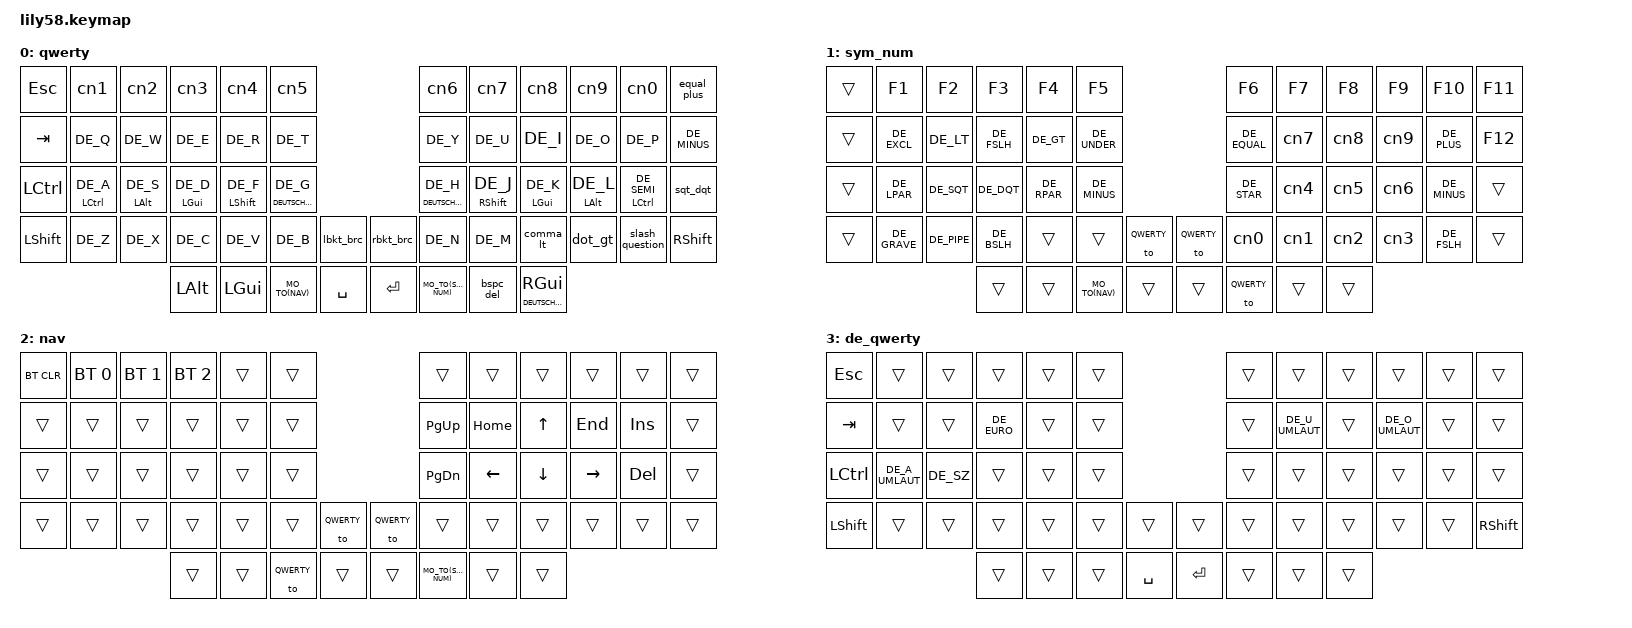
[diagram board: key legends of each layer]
#define HOST_OS 2

#include <behaviors.dtsi>
#include <dt-bindings/zmk/keys.h>
#include <dt-bindings/zmk/bt.h>
#include <dt-bindings/zmk/ext_power.h>
#include <dt-bindings/zmk/outputs.h>
#include <locale/keys_de.h>

#include "zmk-helpers/helper.h"
#include "zmk-helpers/key-labels/lily58.h"
#include "zmk-helpers/unicode-chars/german.dtsi"

#include "custom_numbers.h"

#define ___ &trans

// left hand keys
#define KEYS_L LT5 LT4 LT3 LT2 LT1 LT0 LM5 LM4 LM3 LM2 LM1 LM0 LB5 LB4 LB3 LB2 LB1 LB0 LF5 LF4 LF3 LF2 LF1 LF0 LEC
// right hand keys
#define KEYS_R RT5 RT4 RT3 RT2 RT1 RT0 RM5 RM4 RM3 RM2 RM1 RM0 RB5 RB4 RB3 RB2 RB1 RB0 RF5 RF4 RF3 RF2 RF1 RF0 REC
// thumb keys
#define THUMBS LH3 LH2 LH1 LH0 RH0 RH1 RH2 RH3

// layer definitions
#define QWERTY          0
#define SYM_NUM         1
#define NAV             2
#define DEUTSCH_QWERTY  3

ZMK_HOLD_TAP(mo_to,
    flavor = "balanced";
    tapping-term-ms = <200>;
    bindings = <&mo>, <&to>;
)

#define MO_TO(layer) &mo_to layer layer

// left-hand HRMs
ZMK_HOLD_TAP(hml,
    flavor = "balanced";
    tapping-term-ms = <280>;
    quick-tap-ms = <175>;                // repeat on tap-into-hold
    require-prior-idle-ms = <150>;
    bindings = <&kp>, <&kp>;
    hold-trigger-key-positions = <KEYS_R THUMBS>;
    hold-trigger-on-release;             // delay positional check until key-release
)

// right-hand HRMs
ZMK_HOLD_TAP(hmr,
    flavor = "balanced";
    tapping-term-ms = <280>;
    quick-tap-ms = <175>;                // repeat on tap-into-hold
    require-prior-idle-ms = <150>;
    bindings = <&kp>, <&kp>;
    hold-trigger-key-positions = <KEYS_L THUMBS>;
    hold-trigger-on-release;             // delay p ositional check until key-release
)

// tap: backspace | shift + tap: delete
ZMK_MOD_MORPH(bspc_del,
     bindings = <&kp BSPC>, <&kp DEL>;
     mods = <(MOD_LSFT|MOD_RSFT)>;
)

#define HRM_CTRL_A &hml LCTRL DE_A
#define HRM_ALT_S &hml LALT DE_S
#define HRM_GUI_D &hml LGUI DE_D
#define HRM_SHIFT_F &hml LSHIFT DE_F
#define HRM_DQ_G &lt DEUTSCH_QWERTY DE_G
#define HRM_DQ_H &lt DEUTSCH_QWERTY DE_H
#define HRM_SHIFT_J &hmr RSHIFT DE_J
#define HRM_GUI_K &hmr LGUI DE_K
#define HRM_ALT_L &hmr LALT DE_L
#define HRM_CTRL_SEMI &hmr LCTRL DE_SEMI
ZMK_LAYER(qwerty,
    // ╭────────────────┬────────────────┬────────────────┬────────────────┬────────────────┬────────────────┬────────────────╮╭────────────────┬────────────────┬────────────────┬────────────────┬────────────────┬────────────────┬────────────────╮
         &kp ESC          &cn1             &cn2             &cn3             &cn4             &cn5                                                &cn6             &cn7             &cn8             &cn9             &cn0             &equal_plus
    // ├────────────────┼────────────────┼────────────────┼────────────────┼────────────────┤────────────────┤────────────────┤├────────────────┼────────────────┼────────────────┼────────────────┼────────────────┤────────────────┤────────────────┤
         &kp TAB          &kp DE_Q         &kp DE_W         &kp DE_E         &kp DE_R         &kp DE_T                                            &kp DE_Y         &kp DE_U         &kp DE_I         &kp DE_O         &kp DE_P         &kp DE_MINUS
    // ├────────────────┼────────────────┼────────────────┼────────────────┼────────────────┤────────────────┤────────────────┤├────────────────┼────────────────┼────────────────┼────────────────┼────────────────┤────────────────┤────────────────┤
         &kp LCTRL        HRM_CTRL_A       HRM_ALT_S        HRM_GUI_D        HRM_SHIFT_F      HRM_DQ_G                                            HRM_DQ_H         HRM_SHIFT_J      HRM_GUI_K        HRM_ALT_L        HRM_CTRL_SEMI    &sqt_dqt
    // ├────────────────┼────────────────┼────────────────┼────────────────┼────────────────┤────────────────┤────────────────┤├────────────────┼────────────────┼────────────────┼────────────────┼────────────────┤────────────────┤────────────────┤
         &kp LSHFT        &kp DE_Z         &kp DE_X         &kp DE_C         &kp DE_V         &kp DE_B         &lbkt_brc         &rbkt_brc        &kp DE_N         &kp DE_M         &comma_lt        &dot_gt          &slash_question  &kp RSHIFT
    // ├────────────────┼────────────────┼────────────────┼────────────────┼────────────────┤────────────────┤────────────────┤├────────────────┼────────────────┼────────────────┼────────────────┼────────────────┤────────────────┤────────────────┤
                                                            &kp LALT         &kp LGUI         MO_TO(NAV)       &kp SPACE         &kp ENTER        MO_TO(SYM_NUM)   &bspc_del        &lt DEUTSCH_QWERTY RGUI
    //                                                    ╰────────────────┴────────────────┴────────────────┴────────────────╯╰────────────────┴────────────────┴────────────────┴────────────────╯
)

ZMK_LAYER(sym_num,
    // ╭────────────────┬────────────────┬────────────────┬────────────────┬────────────────┬────────────────┬────────────────╮╭────────────────┬────────────────┬────────────────┬────────────────┬────────────────┬────────────────┬────────────────╮
         ___              &kp F1           &kp F2           &kp F3           &kp F4           &kp F5                                              &kp F6           &kp F7           &kp F8           &kp F9           &kp F10          &kp F11      
    // ├────────────────┼────────────────┼────────────────┼────────────────┼────────────────┤────────────────┤────────────────┤├────────────────┼────────────────┼────────────────┼────────────────┼────────────────┤────────────────┤────────────────┤
         ___              &kp DE_EXCL      &kp DE_LT        &kp DE_FSLH      &kp DE_GT        &kp DE_UNDER                                        &kp DE_EQUAL     &cn7             &cn8             &cn9             &kp DE_PLUS      &kp F12
    // ├────────────────┼────────────────┼────────────────┼────────────────┼────────────────┤────────────────┤────────────────┤├────────────────┼────────────────┼────────────────┼────────────────┼────────────────┤────────────────┤────────────────┤
         ___              &kp DE_LPAR      &kp DE_SQT       &kp DE_DQT       &kp DE_RPAR      &kp DE_MINUS                                        &kp DE_STAR      &cn4             &cn5             &cn6             &kp DE_MINUS     ___
    // ├────────────────┼────────────────┼────────────────┼────────────────┼────────────────┤────────────────┤────────────────┤├────────────────┼────────────────┼────────────────┼────────────────┼────────────────┤────────────────┤────────────────┤
         ___              &kp DE_GRAVE     &kp DE_PIPE      &kp DE_BSLH      ___              ___              &to QWERTY        &to QWERTY       &cn0             &cn1             &cn2             &cn3             &kp DE_FSLH      ___
    // ├────────────────┼────────────────┼────────────────┼────────────────┼────────────────┤────────────────┤────────────────┤├────────────────┼────────────────┼────────────────┼────────────────┼────────────────┤────────────────┤────────────────┤
                                                            ___              ___              MO_TO(NAV)       ___               ___              &to QWERTY       ___              ___
    //                                                    ╰────────────────┴────────────────┴────────────────┴────────────────╯╰────────────────┴────────────────┴────────────────┴────────────────╯
)

ZMK_LAYER(nav,
    // ╭────────────────┬────────────────┬────────────────┬────────────────┬────────────────┬────────────────┬────────────────╮╭────────────────┬────────────────┬────────────────┬────────────────┬────────────────┬────────────────┬────────────────╮
         &bt BT_CLR       &bt BT_SEL 0     &bt BT_SEL 1     &bt BT_SEL 2     ___              ___                                                 ___              ___              ___              ___              ___              ___
    // ├────────────────┼────────────────┼────────────────┼────────────────┼────────────────┤────────────────┤────────────────┤├────────────────┼────────────────┼────────────────┼────────────────┼────────────────┤────────────────┤────────────────┤
         ___              ___              ___              ___              ___              ___                                                 &kp PG_UP        &kp HOME         &kp UP           &kp END          &kp INS          ___
    // ├────────────────┼────────────────┼────────────────┼────────────────┼────────────────┤────────────────┤────────────────┤├────────────────┼────────────────┼────────────────┼────────────────┼────────────────┤────────────────┤────────────────┤
         ___              ___              ___              ___              ___              ___                                                 &kp PG_DN        &kp LEFT         &kp DOWN         &kp RIGHT        &kp DEL          ___
    // ├────────────────┼────────────────┼────────────────┼────────────────┼────────────────┤────────────────┤────────────────┤├────────────────┼────────────────┼────────────────┼────────────────┼────────────────┤────────────────┤────────────────┤
         ___              ___              ___              ___              ___              ___              &to QWERTY        &to QWERTY       ___              ___              ___              ___              ___              ___
    // ├────────────────┼────────────────┼────────────────┼────────────────┼────────────────┤────────────────┤────────────────┤├────────────────┼────────────────┼────────────────┼────────────────┼────────────────┤────────────────┤────────────────┤
                                                            ___              ___              &to QWERTY       ___               ___              MO_TO(SYM_NUM)    ___              ___
    //                                                    ╰────────────────┴────────────────┴────────────────┴────────────────╯╰────────────────┴────────────────┴────────────────┴────────────────╯
)

ZMK_LAYER(de_qwerty,
    // ╭────────────────┬────────────────┬────────────────┬────────────────┬────────────────┬────────────────┬────────────────╮╭────────────────┬────────────────┬────────────────┬────────────────┬────────────────┬────────────────┬────────────────╮
         &kp ESC          ___              ___              ___              ___              ___                                                 ___              ___              ___              ___              ___              ___
    // ├────────────────┼────────────────┼────────────────┼────────────────┼────────────────┤────────────────┤────────────────┤├────────────────┼────────────────┼────────────────┼────────────────┼────────────────┤────────────────┤────────────────┤
         &kp TAB          ___              ___              &kp DE_EURO      ___              ___                                                 ___              &kp DE_U_UMLAUT  ___              &kp DE_O_UMLAUT  ___              ___
    // ├────────────────┼────────────────┼────────────────┼────────────────┼────────────────┤────────────────┤────────────────┤├────────────────┼────────────────┼────────────────┼────────────────┼────────────────┤────────────────┤────────────────┤
         &kp LCTRL        &kp DE_A_UMLAUT  &kp DE_SZ        ___              ___              ___                                                 ___              ___              ___              ___              ___              ___
    // ├────────────────┼────────────────┼────────────────┼────────────────┼────────────────┤────────────────┤────────────────┤├────────────────┼────────────────┼────────────────┼────────────────┼────────────────┤────────────────┤────────────────┤
         &kp LSHFT        ___              ___              ___              ___              ___              ___               ___              ___              ___              ___              ___              ___              &kp RSHIFT
    // ├────────────────┼────────────────┼────────────────┼────────────────┼────────────────┤────────────────┤────────────────┤├────────────────┼────────────────┼────────────────┼────────────────┼────────────────┤────────────────┤────────────────┤
                                                            ___              ___              ___              &kp SPACE         &kp ENTER        ___              ___              ___
    //                                                    ╰────────────────┴────────────────┴────────────────┴────────────────╯╰────────────────┴────────────────┴────────────────┴────────────────╯
)

//ZMK_LAYER(empty,
    // ╭────────────────┬────────────────┬────────────────┬────────────────┬────────────────┬────────────────┬────────────────╮╭────────────────┬────────────────┬────────────────┬────────────────┬────────────────┬────────────────┬────────────────╮
//         ___              ___             ___              ___              ___              ___                                                 ___              ___              ___              ___              ___              ___
    // ├────────────────┼────────────────┼────────────────┼────────────────┼────────────────┤────────────────┤────────────────┤├────────────────┼────────────────┼────────────────┼────────────────┼────────────────┤────────────────┤────────────────┤
//         ___              ___             ___              ___              ___              ___                                                 ___              ___              ___              ___              ___              ___
    // ├────────────────┼────────────────┼────────────────┼────────────────┼────────────────┤────────────────┤────────────────┤├────────────────┼────────────────┼────────────────┼────────────────┼────────────────┤────────────────┤────────────────┤
//         ___              ___             ___              ___              ___              ___                                                 ___              ___              ___              ___              ___              ___
    // ├────────────────┼────────────────┼────────────────┼────────────────┼────────────────┤────────────────┤────────────────┤├────────────────┼────────────────┼────────────────┼────────────────┼────────────────┤────────────────┤────────────────┤
//         ___              ___             ___              ___              ___              ___                                                 ___              ___              ___              ___              ___              ___
    // ├────────────────┼────────────────┼────────────────┼────────────────┼────────────────┤────────────────┤────────────────┤├────────────────┼────────────────┼────────────────┼────────────────┼────────────────┤────────────────┤────────────────┤
//                                                           ___              ___              ___              ___               ___              ___              ___              ___
    //                                                    ╰────────────────┴────────────────┴────────────────┴────────────────╯╰────────────────┴────────────────┴────────────────┴────────────────╯
//)
